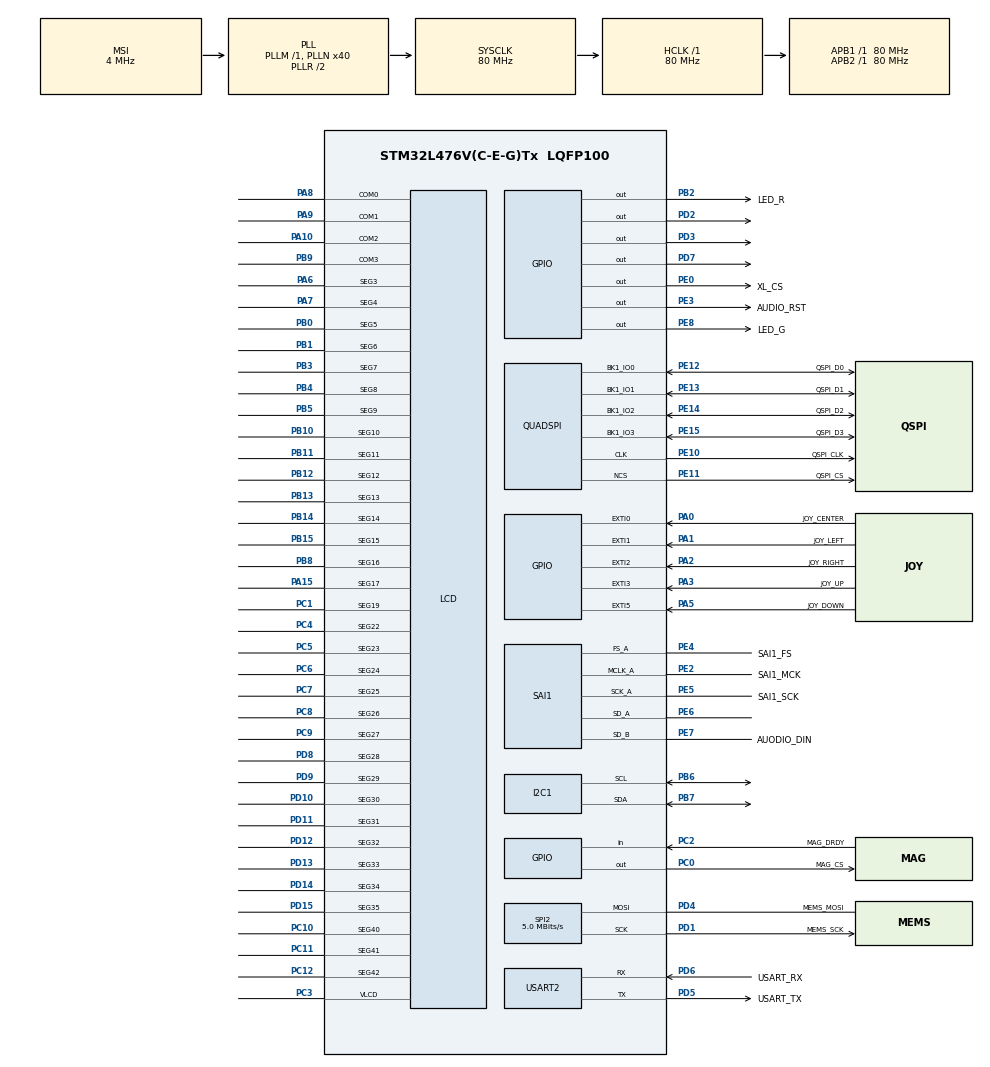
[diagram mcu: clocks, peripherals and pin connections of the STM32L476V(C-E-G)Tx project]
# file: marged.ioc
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Dma.Request0=USART2_RX
Dma.Request1=USART2_TX
Dma.USART2_RX.0.Direction=DMA_PERIPH_TO_MEMORY
Dma.USART2_RX.0.Instance=DMA1_Channel6
Dma.USART2_RX.0.MemDataAlignment=DMA_MDATAALIGN_BYTE
Dma.USART2_RX.0.MemInc=DMA_MINC_ENABLE
Dma.USART2_RX.0.Mode=DMA_NORMAL
Dma.USART2_RX.0.PeriphDataAlignment=DMA_PDATAALIGN_BYTE
Dma.USART2_RX.0.PeriphInc=DMA_PINC_DISABLE
Dma.USART2_RX.0.Priority=DMA_PRIORITY_LOW
Dma.USART2_TX.1.Direction=DMA_MEMORY_TO_PERIPH
Dma.USART2_TX.1.Instance=DMA1_Channel7
Dma.USART2_TX.1.MemDataAlignment=DMA_MDATAALIGN_BYTE
Dma.USART2_TX.1.MemInc=DMA_MINC_ENABLE
Dma.USART2_TX.1.Mode=DMA_NORMAL
Dma.USART2_TX.1.PeriphDataAlignment=DMA_PDATAALIGN_BYTE
Dma.USART2_TX.1.PeriphInc=DMA_PINC_DISABLE
Dma.USART2_TX.1.Priority=DMA_PRIORITY_LOW
Mcu.Family=STM32L4
Mcu.Name=STM32L476V(C-E-G)Tx
Mcu.Package=LQFP100
NVIC.DMA1_Channel6_IRQn=true\:0\:0\:false\:false\:true\:false\:true
NVIC.DMA1_Channel7_IRQn=true\:0\:0\:false\:false\:true\:false\:true
NVIC.EXTI0_IRQn=true\:0\:0\:false\:false\:true\:true\:true
NVIC.EXTI1_IRQn=true\:0\:0\:false\:false\:true\:true\:true
NVIC.EXTI2_IRQn=true\:0\:0\:false\:false\:true\:true\:true
NVIC.EXTI3_IRQn=true\:0\:0\:false\:false\:true\:true\:true
NVIC.EXTI9_5_IRQn=true\:0\:0\:false\:false\:true\:true\:true
NVIC.PriorityGroup=NVIC_PRIORITYGROUP_4
NVIC.USART2_IRQn=true\:0\:0\:false\:false\:true\:true\:true
PA0.GPIO_Label=JOY_CENTER
PA0.GPIO_PuPd=GPIO_PULLUP
PA0.Signal=GPXTI0
PA1.GPIO_Label=JOY_LEFT
PA1.GPIO_PuPd=GPIO_PULLDOWN
PA1.Signal=GPXTI1
PA10.Mode=1/4 Duty Cycle
PA10.Signal=LCD_COM2
PA15\ (JTDI).Mode=SEG17
PA15\ (JTDI).Signal=LCD_SEG17
PA2.GPIO_Label=JOY_RIGHT
PA2.GPIO_PuPd=GPIO_PULLDOWN
PA2.Signal=GPXTI2
PA3.GPIO_Label=JOY_UP
PA3.GPIO_PuPd=GPIO_PULLDOWN
PA3.Signal=GPXTI3
PA5.GPIO_Label=JOY_DOWN
PA5.GPIO_PuPd=GPIO_PULLDOWN
PA5.Signal=GPXTI5
PA6.Mode=SEG3
PA6.Signal=LCD_SEG3
PA7.Mode=SEG4
PA7.Signal=LCD_SEG4
PA8.Mode=1/4 Duty Cycle
PA8.Signal=LCD_COM0
PA9.Mode=1/4 Duty Cycle
PA9.Signal=LCD_COM1
PB0.Mode=SEG5
PB0.Signal=LCD_SEG5
PB1.Mode=SEG6
PB1.Signal=LCD_SEG6
PB10.Mode=SEG10
PB10.Signal=LCD_SEG10
PB11.Mode=SEG11
PB11.Signal=LCD_SEG11
PB12.Mode=SEG12
PB12.Signal=LCD_SEG12
PB13.Mode=SEG13
PB13.Signal=LCD_SEG13
PB14.Mode=SEG14
PB14.Signal=LCD_SEG14
PB15.Mode=SEG15
PB15.Signal=LCD_SEG15
PB2.GPIO_Label=LED_R
PB2.Signal=GPIO_Output
PB3\ (JTDO-TRACESWO).Mode=SEG7
PB3\ (JTDO-TRACESWO).Signal=LCD_SEG7
PB4\ (NJTRST).Mode=SEG8
PB4\ (NJTRST).Signal=LCD_SEG8
PB5.Mode=SEG9
PB5.Signal=LCD_SEG9
PB6.Mode=I2C
PB6.Signal=I2C1_SCL
PB7.Mode=I2C
PB7.Signal=I2C1_SDA
PB8.Mode=SEG16
PB8.Signal=LCD_SEG16
PB9.Mode=1/4 Duty Cycle
PB9.Signal=LCD_COM3
PC0.GPIO_Label=MAG_CS
PC0.Signal=GPIO_Output
PC1.Mode=SEG19
PC1.Signal=LCD_SEG19
PC10.Mode=SEG40
PC10.Signal=LCD_SEG40
PC11.Mode=SEG41
PC11.Signal=LCD_SEG41
PC12.Mode=SEG42
PC12.Signal=LCD_SEG42
PC2.GPIO_Label=MAG_DRDY
PC2.Signal=GPIO_Input
PC3.Mode=1/4 Duty Cycle
PC3.Signal=LCD_VLCD
PC4.Mode=SEG22
PC4.Signal=LCD_SEG22
PC5.Mode=SEG23
PC5.Signal=LCD_SEG23
PC6.Mode=SEG24
PC6.Signal=LCD_SEG24
PC7.Mode=SEG25
PC7.Signal=LCD_SEG25
PC8.Mode=SEG26
PC8.Signal=LCD_SEG26
PC9.Mode=SEG27
PC9.Signal=LCD_SEG27
PD1.GPIO_Label=MEMS_SCK
PD1.Mode=Simplex_Bidirectional_Master
PD1.Signal=SPI2_SCK
PD10.Mode=SEG30
PD10.Signal=LCD_SEG30
PD11.Mode=SEG31
PD11.Signal=LCD_SEG31
PD12.Mode=SEG32
PD12.Signal=LCD_SEG32
PD13.Mode=SEG33
PD13.Signal=LCD_SEG33
PD14.Mode=SEG34
PD14.Signal=LCD_SEG34
PD15.Mode=SEG35
PD15.Signal=LCD_SEG35
PD2.Signal=GPIO_Output
PD3.Signal=GPIO_Output
PD4.GPIO_Label=MEMS_MOSI
PD4.Mode=Simplex_Bidirectional_Master
PD4.Signal=SPI2_MOSI
PD5.GPIO_Label=USART_TX
PD5.Mode=Asynchronous
PD5.Signal=USART2_TX
PD6.GPIO_Label=USART_RX
PD6.Mode=Asynchronous
PD6.Signal=USART2_RX
PD7.GPIO_Speed=GPIO_SPEED_FREQ_VERY_HIGH
PD7.PinState=GPIO_PIN_RESET
PD7.Signal=GPIO_Output
PD8.Mode=SEG28
PD8.Signal=LCD_SEG28
PD9.Mode=SEG29
PD9.Signal=LCD_SEG29
PE0.GPIO_Label=XL_CS
PE0.Signal=GPIO_Output
PE10.GPIO_Label=QSPI_CLK
PE10.Mode=Single Bank
PE10.Signal=QUADSPI_CLK
PE11.GPIO_Label=QSPI_CS
PE11.Mode=Single Bank
PE11.Signal=QUADSPI_NCS
PE12.GPIO_Label=QSPI_D0
PE12.Mode=Single Bank
PE12.Signal=QUADSPI_BK1_IO0
PE13.GPIO_Label=QSPI_D1
PE13.Mode=Single Bank
PE13.Signal=QUADSPI_BK1_IO1
PE14.GPIO_Label=QSPI_D2
PE14.Mode=Single Bank
PE14.Signal=QUADSPI_BK1_IO2
PE15.GPIO_Label=QSPI_D3
PE15.Mode=Single Bank
PE15.Signal=QUADSPI_BK1_IO3
PE2.GPIO_Label=SAI1_MCK
PE2.Mode=SAI_A_MasterWithClock
PE2.Signal=SAI1_MCLK_A
PE3.GPIO_Label=AUDIO_RST
PE3.Signal=GPIO_Output
PE4.GPIO_Label=SAI1_FS
PE4.Mode=SAI_A_MasterWithClock
PE4.Signal=SAI1_FS_A
PE5.GPIO_Label=SAI1_SCK
PE5.Mode=SAI_A_MasterWithClock
PE5.Signal=SAI1_SCK_A
PE6.Mode=SAI_A_MasterWithClock
PE6.Signal=SAI1_SD_A
PE7.GPIO_Label=AUODIO_DIN
PE7.Mode=SAI_B_SPDIF
PE7.Signal=SAI1_SD_B
PE8.GPIO_Label=LED_G
PE8.Signal=GPIO_Output
PE9.GPIO_Label=AOUDIO_CLK
PE9.Signal=SAI1_FS_B
ProjectManager.HeapSize=0x200
ProjectManager.StackSize=0x400
ProjectManager.TargetToolchain=TrueSTUDIO
QUADSPI.ClockPrescaler-Single\ Bank=255
RCC.ADCFreq_Value=32000000
RCC.AHBFreq_Value=80000000
RCC.APB1Freq_Value=80000000
RCC.APB1TimFreq_Value=80000000
RCC.APB2Freq_Value=80000000
RCC.APB2TimFreq_Value=80000000
RCC.CortexFreq_Value=80000000
RCC.HCLKFreq_Value=80000000
RCC.HSE_VALUE=8000000
RCC.HSI_VALUE=16000000
RCC.LSE_VALUE=32768
RCC.MSI_VALUE=4000000
RCC.PLLN=40
RCC.PLLSAI1N=16
RCC.PREFETCH_ENABLE=1
RCC.SYSCLKFreq_VALUE=80000000
RCC.SYSCLKSource=RCC_SYSCLKSOURCE_PLLCLK
RCC.USBFreq_Value=32000000
RCC.VCOOutputFreq_Value=160000000
RTC.Format=RTC_FORMAT_BCD
RTC.Hours=8
SAI1.AudioFrequency-SAI_A_MasterWithClock=SAI_AUDIO_FREQUENCY_192K
SAI1.ErrorAudioFreq-SAI_A_MasterWithClock=-81.39 %
SAI1.InitProtocol-SAI_A_MasterWithClock=Enable
SAI1.Instance-SAI_A_MasterWithClock=SAI$Index_Block_A
SAI1.Instance-SAI_B_SPDIF=SAI$Index_Block_B
SAI1.MClockEnable-SAI_A_MasterWithClock=SAI_MASTERCLOCK_ENABLE
SAI1.RealAudioFreq-SAI_A_MasterWithClock=35.714 KHz
SAI1.RealAudioFreq-SAI_B_SPDIF=142.857 KHz
SAI1.VirtualMode-SAI_A_MasterWithClock=VM_MASTER
SAI1.VirtualMode-SAI_B_SPDIF=VM_SPDIF
SAI1.VirtualProtocol-SAI_A_BASIC=VM_BASIC_PROTOCOL
SPI2.BaudRatePrescaler=SPI_BAUDRATEPRESCALER_16
SPI2.CalculateBaudRate=5.0 MBits/s
SPI2.DataSize=SPI_DATASIZE_8BIT
SPI2.Direction=SPI_DIRECTION_1LINE
SPI2.Mode=SPI_MODE_MASTER
SPI2.VirtualType=VM_MASTER
USART2.VirtualMode-Asynchronous=VM_ASYNC
VP_RTC_VS_RTC_Activate.Mode=RTC_Enabled
VP_RTC_VS_RTC_Calendar.Mode=RTC_Calendar
VP_SAI1_VP_$IpInstance_SAIA_SAI_BASIC.Mode=SAI_A_BASIC
board=32L476GDISCOVERY

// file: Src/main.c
/* USER CODE BEGIN Header */
/**
  ******************************************************************************
  * @file           : main.c
  * @brief          : Main program body
  ******************************************************************************
  * @attention
  *
  * <h2><center>&copy; Copyright (c) 2019 STMicroelectronics.
  * All rights reserved.</center></h2>
  *
  * This software component is licensed by ST under BSD 3-Clause license,
  * the "License"; You may not use this file except in compliance with the
  * License. You may obtain a copy of the License at:
  *                        opensource.org/licenses/BSD-3-Clause
  *
  ******************************************************************************
  */
/* USER CODE END Header */

#include "main.h"

#include "menu.h"
#include "myTime.h"
#include <math.h>
#include "maudio.h"
#include "stm32l4xx_hal_rcc.h"
#include "cs43l22.h"

//void HAL_SAI_MspInit(SAI_HandleTypeDef *hsai);

I2C_HandleTypeDef hi2c1;

LCD_HandleTypeDef hlcd;

QSPI_HandleTypeDef hqspi;

RTC_HandleTypeDef hrtc;

SAI_HandleTypeDef hsai_BlockB1;
extern SAI_HandleTypeDef hsai_BlockA1;

SPI_HandleTypeDef hspi2;

UART_HandleTypeDef huart2;
DMA_HandleTypeDef hdma_usart2_rx;
DMA_HandleTypeDef hdma_usart2_tx;

/* USER CODE BEGIN PV */

extern AUDIO_DrvTypeDef            *audio_drv;
/* USER CODE END PV */

void SystemClock_Config(void);
static void MX_GPIO_Init(void);
static void MX_DMA_Init(void);
static void MX_QUADSPI_Init(void);
static void MX_SAI1_Init(void);
static void MX_LCD_Init(void);
static void MX_I2C1_Init(void);
static void MX_RTC_Init(void);
static void MX_USART2_UART_Init(void);
static void MX_SPI2_Init(void);
/* USER CODE BEGIN PFP */
void HAL_GPIO_EXTI_Callback(uint16_t GPIO_Pin);
/* USER CODE END PFP */

int main(void)
{

  /* MCU Configuration--------------------------------------------------------*/

  /* Reset of all peripherals, Initializes the Flash interface and the Systick. */

	HAL_Init();

  /* USER CODE BEGIN Init */
	__IO int16_t                 UpdatePointer = -1;
  /* USER CODE END Init */

  /* Configure the system clock */
  SystemClock_Config();

  /* Initialize all configured peripherals */
  MX_GPIO_Init();
  MX_DMA_Init();
  MX_QUADSPI_Init();
  MX_SAI1_Init();
  MX_LCD_Init();
  MX_I2C1_Init();
  MX_RTC_Init();
  MX_USART2_UART_Init();
  MX_SPI2_Init();
  /* USER CODE BEGIN 2 */
  BSP_LCD_GLASS_Init();
  BSP_QSPI_Init();

  HAL_SAI_MspInit2(&hsai_BlockA1);
  Playback_Init();
  AKC_Init();
  /* USER CODE END 2 */

  /* Infinite loop */
  /* USER CODE BEGIN WHILE */
  uint16_t PlayBuff[PLAY_BUFF_SIZE];

  if(0 != audio_drv->Play(AUDIO_I2C_ADDRESS, NULL, 0))
    {
      Error_Handler();
    }

  for(int i=0; i < PLAY_BUFF_SIZE; i+=2)
    {
      PlayBuff[i]=*((__IO uint16_t *)(AUDIO_FILE_ADDRESS + PLAY_HEADER + i));
    }

  int j = 0;
  for(int i = 0; i < PLAY_BUFF_SIZE/4; i++)
  {
     PlayBuff[i] = i;
  }
  j=PLAY_BUFF_SIZE/4;
  for(int i = 0; i < PLAY_BUFF_SIZE/2; i++)
  {
     PlayBuff[i] = j-i;
  }
  j=-PLAY_BUFF_SIZE/4;
  for(int i = 0; i < PLAY_BUFF_SIZE/4; i++)
  {
      PlayBuff[i] = j+i;
  }

//
HAL_SAI_Transmit_DMA(&hsai_BlockA1, (uint8_t *)PlayBuff, PLAY_BUFF_SIZE);

HAL_SAI_DMAPause(&hsai_BlockA1);
//  {
///   Error_Handler();
//  }

//  for(int i = 0; i < PLAY_BUFF_SIZE; i++)
 //   {
 //       PlayBuff[i] = 0;
 //   }

//  HAL_Delay(2000);
//  cs43l22_Pause(AUDIO_I2C_ADDRESS);

 // AUDIO_IO_Init();
 // AUDIO_IO_Write(,,PlayBuff)

  while (1)
  {

	//  if(joy_event == fJOY_CENTER)
	//  {
	//	  __RESET_JOY(joy_event);
	//	  PetlaMenu();
	//  }
	//  strcpy(x,"\0\0\0\0");
	  /*
	  BSP_LCD_GLASS_Clear();

	  t_minus_jeden = sqrt(spiRxBufx[0]*spiRxBufx[0] + spiRxBufy[0]*spiRxBufy[0] + spiRxBufz[0] * spiRxBufz[0]);

	  AKC_Pomiar();
	  t_0 = sqrt(spiRxBufx[0]*spiRxBufx[0] + spiRxBufy[0]*spiRxBufy[0] + spiRxBufz[0] * spiRxBufz[0]);

	  rozniczkujemy = min(t_0 - t_minus_jeden, t_minus_jeden - t_0);

	  max1 = max(max1,rozniczkujemy);
	  itoa(max1,x,10);

	  BSP_LCD_GLASS_DisplayString(x);

*/
	  if(joy_event == fJOY_CENTER)
	  {
	  	  __RESET_JOY(joy_event);
	  	  PetlaMenu();

	  }

	  HAL_Delay(100);
	  DrawTime(&hrtc);

  }
  /* USER CODE END 3 */
}

void HAL_GPIO_EXTI_Callback(uint16_t GPIO_Pin)
{
	//HAL_GPIO_TogglePin(GPIOB, LED_R_Pin);

	switch(GPIO_Pin)
	{
	case JOY_CENTER_Pin:
		joy_event = fJOY_CENTER;
		break;
	case JOY_DOWN_Pin:
		joy_event = fJOY_DOWN;
		return;
	case JOY_LEFT_Pin:
		joy_event = fJOY_LEFT;
		break;
	case JOY_RIGHT_Pin:
		joy_event = fJOY_RIGHT;
		break;
	case JOY_UP_Pin:
		joy_event = fJOY_UP;
		break;
	default:
		//dioda sygnalizujaca bledy
		HAL_GPIO_WritePin(GPIOB,LED_R_Pin,GPIO_PIN_SET);
	break;
	}
	return;
}

void SystemClock_Config(void)
{
  RCC_OscInitTypeDef RCC_OscInitStruct = {0};
  RCC_ClkInitTypeDef RCC_ClkInitStruct = {0};
  RCC_PeriphCLKInitTypeDef PeriphClkInit = {0};

  /** Initializes the CPU, AHB and APB busses clocks
  */
  RCC_OscInitStruct.OscillatorType = RCC_OSCILLATORTYPE_LSI|RCC_OSCILLATORTYPE_MSI;
  RCC_OscInitStruct.LSIState = RCC_LSI_ON;
  RCC_OscInitStruct.MSIState = RCC_MSI_ON;
  RCC_OscInitStruct.MSICalibrationValue = 0;
  RCC_OscInitStruct.MSIClockRange = RCC_MSIRANGE_6;
  RCC_OscInitStruct.PLL.PLLState = RCC_PLL_ON;
  RCC_OscInitStruct.PLL.PLLSource = RCC_PLLSOURCE_MSI;
  RCC_OscInitStruct.PLL.PLLM = 1;
  RCC_OscInitStruct.PLL.PLLN = 40;
  RCC_OscInitStruct.PLL.PLLP = RCC_PLLP_DIV7;
  RCC_OscInitStruct.PLL.PLLQ = RCC_PLLQ_DIV2;
  RCC_OscInitStruct.PLL.PLLR = RCC_PLLR_DIV2;
  if (HAL_RCC_OscConfig(&RCC_OscInitStruct) != HAL_OK)
  {
    Error_Handler();
  }
  /** Initializes the CPU, AHB and APB busses clocks
  */
  RCC_ClkInitStruct.ClockType = RCC_CLOCKTYPE_HCLK|RCC_CLOCKTYPE_SYSCLK
                              |RCC_CLOCKTYPE_PCLK1|RCC_CLOCKTYPE_PCLK2;
  RCC_ClkInitStruct.SYSCLKSource = RCC_SYSCLKSOURCE_PLLCLK;
  RCC_ClkInitStruct.AHBCLKDivider = RCC_SYSCLK_DIV1;
  RCC_ClkInitStruct.APB1CLKDivider = RCC_HCLK_DIV1;
  RCC_ClkInitStruct.APB2CLKDivider = RCC_HCLK_DIV1;

  if (HAL_RCC_ClockConfig(&RCC_ClkInitStruct, FLASH_LATENCY_4) != HAL_OK)
  {
    Error_Handler();
  }
  PeriphClkInit.PeriphClockSelection = RCC_PERIPHCLK_RTC|RCC_PERIPHCLK_USART2
                              |RCC_PERIPHCLK_SAI1|RCC_PERIPHCLK_I2C1;
  PeriphClkInit.Usart2ClockSelection = RCC_USART2CLKSOURCE_PCLK1;
  PeriphClkInit.I2c1ClockSelection = RCC_I2C1CLKSOURCE_PCLK1;
  PeriphClkInit.Sai1ClockSelection = RCC_SAI1CLKSOURCE_PLLSAI1;
  PeriphClkInit.RTCClockSelection = RCC_RTCCLKSOURCE_LSI;
  PeriphClkInit.PLLSAI1.PLLSAI1Source = RCC_PLLSOURCE_MSI;
  PeriphClkInit.PLLSAI1.PLLSAI1M = 1;
  PeriphClkInit.PLLSAI1.PLLSAI1N = 16;
  PeriphClkInit.PLLSAI1.PLLSAI1P = RCC_PLLP_DIV7;
  PeriphClkInit.PLLSAI1.PLLSAI1Q = RCC_PLLQ_DIV2;
  PeriphClkInit.PLLSAI1.PLLSAI1R = RCC_PLLR_DIV2;
  PeriphClkInit.PLLSAI1.PLLSAI1ClockOut = RCC_PLLSAI1_SAI1CLK;
  if (HAL_RCCEx_PeriphCLKConfig(&PeriphClkInit) != HAL_OK)
  {
    Error_Handler();
  }
  /** Configure the main internal regulator output voltage
  */
  if (HAL_PWREx_ControlVoltageScaling(PWR_REGULATOR_VOLTAGE_SCALE1) != HAL_OK)
  {
    Error_Handler();
  }

}

static void MX_I2C1_Init(void)
{

  hi2c1.Instance = I2C1;
  hi2c1.Init.Timing = 0x10909CEC;
  hi2c1.Init.OwnAddress1 = 0;
  hi2c1.Init.AddressingMode = I2C_ADDRESSINGMODE_7BIT;
  hi2c1.Init.DualAddressMode = I2C_DUALADDRESS_DISABLE;
  hi2c1.Init.OwnAddress2 = 0;
  hi2c1.Init.OwnAddress2Masks = I2C_OA2_NOMASK;
  hi2c1.Init.GeneralCallMode = I2C_GENERALCALL_DISABLE;
  hi2c1.Init.NoStretchMode = I2C_NOSTRETCH_DISABLE;
  if (HAL_I2C_Init(&hi2c1) != HAL_OK)
  {
    Error_Handler();
  }
  /** Configure Analogue filter
  */
  if (HAL_I2CEx_ConfigAnalogFilter(&hi2c1, I2C_ANALOGFILTER_ENABLE) != HAL_OK)
  {
    Error_Handler();
  }
  /** Configure Digital filter
  */
  if (HAL_I2CEx_ConfigDigitalFilter(&hi2c1, 0) != HAL_OK)
  {
    Error_Handler();
  }

}

static void MX_LCD_Init(void)
{

  hlcd.Instance = LCD;
  hlcd.Init.Prescaler = LCD_PRESCALER_1;
  hlcd.Init.Divider = LCD_DIVIDER_16;
  hlcd.Init.Duty = LCD_DUTY_1_4;
  hlcd.Init.Bias = LCD_BIAS_1_4;
  hlcd.Init.VoltageSource = LCD_VOLTAGESOURCE_INTERNAL;
  hlcd.Init.Contrast = LCD_CONTRASTLEVEL_0;
  hlcd.Init.DeadTime = LCD_DEADTIME_0;
  hlcd.Init.PulseOnDuration = LCD_PULSEONDURATION_0;
  hlcd.Init.MuxSegment = LCD_MUXSEGMENT_DISABLE;
  hlcd.Init.BlinkMode = LCD_BLINKMODE_OFF;
  hlcd.Init.BlinkFrequency = LCD_BLINKFREQUENCY_DIV8;
  hlcd.Init.HighDrive = LCD_HIGHDRIVE_DISABLE;
  if (HAL_LCD_Init(&hlcd) != HAL_OK)
  {
    Error_Handler();
  }

}

static void MX_QUADSPI_Init(void)
{

  /* QUADSPI parameter configuration*/
  hqspi.Instance = QUADSPI;
  hqspi.Init.ClockPrescaler = 255;
  hqspi.Init.FifoThreshold = 1;
  hqspi.Init.SampleShifting = QSPI_SAMPLE_SHIFTING_NONE;
  hqspi.Init.FlashSize = 1;
  hqspi.Init.ChipSelectHighTime = QSPI_CS_HIGH_TIME_1_CYCLE;
  hqspi.Init.ClockMode = QSPI_CLOCK_MODE_0;
  if (HAL_QSPI_Init(&hqspi) != HAL_OK)
  {
    Error_Handler();
  }

}

static void MX_RTC_Init(void)
{

  RTC_TimeTypeDef sTime = {0};
  RTC_DateTypeDef sDate = {0};

  /** Initialize RTC Only
  */
  hrtc.Instance = RTC;
  hrtc.Init.HourFormat = RTC_HOURFORMAT_24;
  hrtc.Init.AsynchPrediv = 127;
  hrtc.Init.SynchPrediv = 255;
  hrtc.Init.OutPut = RTC_OUTPUT_DISABLE;
  hrtc.Init.OutPutRemap = RTC_OUTPUT_REMAP_NONE;
  hrtc.Init.OutPutPolarity = RTC_OUTPUT_POLARITY_HIGH;
  hrtc.Init.OutPutType = RTC_OUTPUT_TYPE_OPENDRAIN;
  if (HAL_RTC_Init(&hrtc) != HAL_OK)
  {
    Error_Handler();
  }

  /** Initialize RTC and set the Time and Date
  */
  sTime.Hours = 0x8;
  sTime.Minutes = 0x0;
  sTime.Seconds = 0x0;
  sTime.DayLightSaving = RTC_DAYLIGHTSAVING_NONE;
  sTime.StoreOperation = RTC_STOREOPERATION_RESET;
  if (HAL_RTC_SetTime(&hrtc, &sTime, RTC_FORMAT_BCD) != HAL_OK)
  {
    Error_Handler();
  }
  sDate.WeekDay = RTC_WEEKDAY_MONDAY;
  sDate.Month = RTC_MONTH_JANUARY;
  sDate.Date = 0x1;
  sDate.Year = 0x0;

  if (HAL_RTC_SetDate(&hrtc, &sDate, RTC_FORMAT_BCD) != HAL_OK)
  {
    Error_Handler();
  }

}

static void MX_SAI1_Init(void)
{

  hsai_BlockB1.Instance = SAI1_Block_B;
  hsai_BlockB1.Init.Protocol = SAI_SPDIF_PROTOCOL;
  hsai_BlockB1.Init.AudioMode = SAI_MODEMASTER_TX;
  hsai_BlockB1.Init.Synchro = SAI_ASYNCHRONOUS;
  hsai_BlockB1.Init.OutputDrive = SAI_OUTPUTDRIVE_DISABLE;
  hsai_BlockB1.Init.FIFOThreshold = SAI_FIFOTHRESHOLD_EMPTY;
  hsai_BlockB1.Init.AudioFrequency = SAI_AUDIO_FREQUENCY_48K;
  hsai_BlockB1.Init.SynchroExt = SAI_SYNCEXT_DISABLE;
  hsai_BlockB1.Init.MonoStereoMode = SAI_STEREOMODE;
  hsai_BlockB1.Init.CompandingMode = SAI_NOCOMPANDING;
  if (HAL_SAI_Init(&hsai_BlockB1) != HAL_OK)
  {
    Error_Handler();
  }
  hsai_BlockA1.Instance = SAI1_Block_A;
  hsai_BlockA1.Init.AudioMode = SAI_MODEMASTER_TX;
  hsai_BlockA1.Init.Synchro = SAI_ASYNCHRONOUS;
  hsai_BlockA1.Init.OutputDrive = SAI_OUTPUTDRIVE_DISABLE;
  hsai_BlockA1.Init.NoDivider = SAI_MASTERDIVIDER_ENABLE;
  hsai_BlockA1.Init.FIFOThreshold = SAI_FIFOTHRESHOLD_EMPTY;
  hsai_BlockA1.Init.AudioFrequency = SAI_AUDIO_FREQUENCY_192K;
  hsai_BlockA1.Init.SynchroExt = SAI_SYNCEXT_DISABLE;
  hsai_BlockA1.Init.MonoStereoMode = SAI_STEREOMODE;
  hsai_BlockA1.Init.CompandingMode = SAI_NOCOMPANDING;
  hsai_BlockA1.Init.TriState = SAI_OUTPUT_NOTRELEASED;
  if (HAL_SAI_InitProtocol(&hsai_BlockA1, SAI_I2S_STANDARD, SAI_PROTOCOL_DATASIZE_16BIT, 2) != HAL_OK)
  {
    Error_Handler();
  }

}

static void MX_SPI2_Init(void)
{

  /* SPI2 parameter configuration*/
  hspi2.Instance = SPI2;
  hspi2.Init.Mode = SPI_MODE_MASTER;
  hspi2.Init.Direction = SPI_DIRECTION_1LINE;
  hspi2.Init.DataSize = SPI_DATASIZE_8BIT;
  hspi2.Init.CLKPolarity = SPI_POLARITY_LOW;
  hspi2.Init.CLKPhase = SPI_PHASE_1EDGE;
  hspi2.Init.NSS = SPI_NSS_SOFT;
  hspi2.Init.BaudRatePrescaler = SPI_BAUDRATEPRESCALER_16;
  hspi2.Init.FirstBit = SPI_FIRSTBIT_MSB;
  hspi2.Init.TIMode = SPI_TIMODE_DISABLE;
  hspi2.Init.CRCCalculation = SPI_CRCCALCULATION_DISABLE;
  hspi2.Init.CRCPolynomial = 7;
  hspi2.Init.CRCLength = SPI_CRC_LENGTH_DATASIZE;
  hspi2.Init.NSSPMode = SPI_NSS_PULSE_ENABLE;
  if (HAL_SPI_Init(&hspi2) != HAL_OK)
  {
    Error_Handler();
  }

}

static void MX_USART2_UART_Init(void)
{

  huart2.Instance = USART2;
  huart2.Init.BaudRate = 115200;
  huart2.Init.WordLength = UART_WORDLENGTH_8B;
  huart2.Init.StopBits = UART_STOPBITS_1;
  huart2.Init.Parity = UART_PARITY_NONE;
  huart2.Init.Mode = UART_MODE_TX_RX;
  huart2.Init.HwFlowCtl = UART_HWCONTROL_NONE;
  huart2.Init.OverSampling = UART_OVERSAMPLING_16;
  huart2.Init.OneBitSampling = UART_ONE_BIT_SAMPLE_DISABLE;
  huart2.AdvancedInit.AdvFeatureInit = UART_ADVFEATURE_NO_INIT;
  if (HAL_UART_Init(&huart2) != HAL_OK)
  {
    Error_Handler();
  }

}

static void MX_DMA_Init(void)
{
  /* DMA controller clock enable */
  __HAL_RCC_DMA1_CLK_ENABLE();

  /* DMA interrupt init */
  /* DMA1_Channel6_IRQn interrupt configuration */
  HAL_NVIC_SetPriority(DMA1_Channel6_IRQn, 0, 0);
  HAL_NVIC_EnableIRQ(DMA1_Channel6_IRQn);
  /* DMA1_Channel7_IRQn interrupt configuration */
  HAL_NVIC_SetPriority(DMA1_Channel7_IRQn, 0, 0);
  HAL_NVIC_EnableIRQ(DMA1_Channel7_IRQn);

}

static void MX_GPIO_Init(void)
{
  GPIO_InitTypeDef GPIO_InitStruct = {0};

  /* GPIO Ports Clock Enable */
  __HAL_RCC_GPIOE_CLK_ENABLE();
  __HAL_RCC_GPIOC_CLK_ENABLE();
  __HAL_RCC_GPIOA_CLK_ENABLE();
  __HAL_RCC_GPIOB_CLK_ENABLE();
  __HAL_RCC_GPIOD_CLK_ENABLE();

  /*Configure GPIO pin Output Level */
  HAL_GPIO_WritePin(GPIOE, AUDIO_RST_Pin|LED_G_Pin|XL_CS_Pin, GPIO_PIN_RESET);

  /*Configure GPIO pin Output Level */
  HAL_GPIO_WritePin(MAG_CS_GPIO_Port, MAG_CS_Pin, GPIO_PIN_RESET);

  /*Configure GPIO pin Output Level */
  HAL_GPIO_WritePin(LED_R_GPIO_Port, LED_R_Pin, GPIO_PIN_RESET);

  /*Configure GPIO pin Output Level */
  HAL_GPIO_WritePin(GPIOD, GPIO_PIN_2|GPIO_PIN_3|GPIO_PIN_7, GPIO_PIN_RESET);

  /*Configure GPIO pins : AUDIO_RST_Pin LED_G_Pin XL_CS_Pin */
  GPIO_InitStruct.Pin = AUDIO_RST_Pin|LED_G_Pin|XL_CS_Pin;
  GPIO_InitStruct.Mode = GPIO_MODE_OUTPUT_PP;
  GPIO_InitStruct.Pull = GPIO_NOPULL;
  GPIO_InitStruct.Speed = GPIO_SPEED_FREQ_LOW;
  HAL_GPIO_Init(GPIOE, &GPIO_InitStruct);

  /*Configure GPIO pin : MAG_CS_Pin */
  GPIO_InitStruct.Pin = MAG_CS_Pin;
  GPIO_InitStruct.Mode = GPIO_MODE_OUTPUT_PP;
  GPIO_InitStruct.Pull = GPIO_NOPULL;
  GPIO_InitStruct.Speed = GPIO_SPEED_FREQ_LOW;
  HAL_GPIO_Init(MAG_CS_GPIO_Port, &GPIO_InitStruct);

  /*Configure GPIO pin : MAG_DRDY_Pin */
  GPIO_InitStruct.Pin = MAG_DRDY_Pin;
  GPIO_InitStruct.Mode = GPIO_MODE_INPUT;
  GPIO_InitStruct.Pull = GPIO_NOPULL;
  HAL_GPIO_Init(MAG_DRDY_GPIO_Port, &GPIO_InitStruct);

  /*Configure GPIO pin : JOY_CENTER_Pin */
  GPIO_InitStruct.Pin = JOY_CENTER_Pin;
  GPIO_InitStruct.Mode = GPIO_MODE_IT_RISING;
  GPIO_InitStruct.Pull = GPIO_PULLUP;
  HAL_GPIO_Init(JOY_CENTER_GPIO_Port, &GPIO_InitStruct);

  /*Configure GPIO pins : JOY_LEFT_Pin JOY_RIGHT_Pin JOY_UP_Pin JOY_DOWN_Pin */
  GPIO_InitStruct.Pin = JOY_LEFT_Pin|JOY_RIGHT_Pin|JOY_UP_Pin|JOY_DOWN_Pin;
  GPIO_InitStruct.Mode = GPIO_MODE_IT_RISING;
  GPIO_InitStruct.Pull = GPIO_PULLDOWN;
  HAL_GPIO_Init(GPIOA, &GPIO_InitStruct);

  /*Configure GPIO pin : LED_R_Pin */
  GPIO_InitStruct.Pin = LED_R_Pin;
  GPIO_InitStruct.Mode = GPIO_MODE_OUTPUT_PP;
  GPIO_InitStruct.Pull = GPIO_NOPULL;
  GPIO_InitStruct.Speed = GPIO_SPEED_FREQ_LOW;
  HAL_GPIO_Init(LED_R_GPIO_Port, &GPIO_InitStruct);

  /*Configure GPIO pins : PD2 PD3 */
  GPIO_InitStruct.Pin = GPIO_PIN_2|GPIO_PIN_3;
  GPIO_InitStruct.Mode = GPIO_MODE_OUTPUT_PP;
  GPIO_InitStruct.Pull = GPIO_NOPULL;
  GPIO_InitStruct.Speed = GPIO_SPEED_FREQ_LOW;
  HAL_GPIO_Init(GPIOD, &GPIO_InitStruct);

  /*Configure GPIO pin : PD7 */
  GPIO_InitStruct.Pin = GPIO_PIN_7;
  GPIO_InitStruct.Mode = GPIO_MODE_OUTPUT_PP;
  GPIO_InitStruct.Pull = GPIO_NOPULL;
  GPIO_InitStruct.Speed = GPIO_SPEED_FREQ_VERY_HIGH;
  HAL_GPIO_Init(GPIOD, &GPIO_InitStruct);

  /* EXTI interrupt init*/
  HAL_NVIC_SetPriority(EXTI0_IRQn, 0, 0);
  HAL_NVIC_EnableIRQ(EXTI0_IRQn);

  HAL_NVIC_SetPriority(EXTI1_IRQn, 0, 0);
  HAL_NVIC_EnableIRQ(EXTI1_IRQn);

  HAL_NVIC_SetPriority(EXTI2_IRQn, 0, 0);
  HAL_NVIC_EnableIRQ(EXTI2_IRQn);

  HAL_NVIC_SetPriority(EXTI3_IRQn, 0, 0);
  HAL_NVIC_EnableIRQ(EXTI3_IRQn);

  HAL_NVIC_SetPriority(EXTI9_5_IRQn, 0, 0);
  HAL_NVIC_EnableIRQ(EXTI9_5_IRQn);

}

void Error_Handler(void)
{
}

/************************ (C) COPYRIGHT STMicroelectronics *****END OF FILE****/
